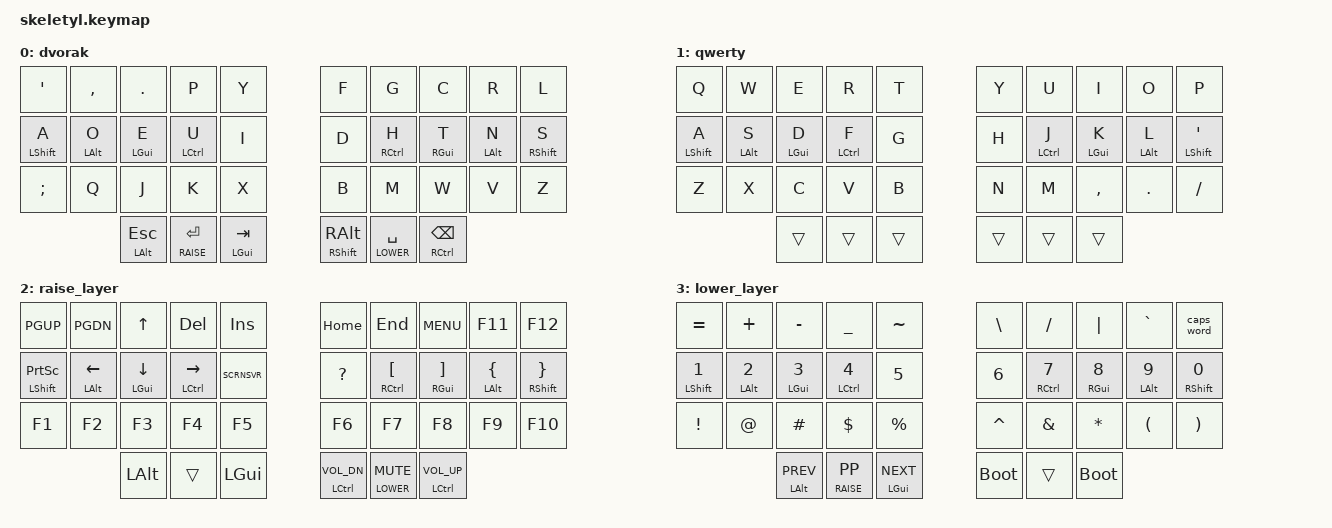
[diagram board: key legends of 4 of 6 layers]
#include <behaviors.dtsi>
#include <dt-bindings/zmk/keys.h>
#include <dt-bindings/zmk/bt.h>
#include <dt-bindings/zmk/pointing.h>
#include <dt-bindings/zmk/outputs.h>
#include "key-labels.h"

// Modified keymap based on personal experience, with some improvements based on Miryoku layout.

#define DVORAK      0
#define QWERTY      1
#define RAISE       2
#define LOWER       3
#define MOUSE       4
#define MOUSE_COND  5

#define REQUIRE_PRIOR_IDLE_MS 150
/* the default value of 280 is too flakey when the interrupting tap is pressed close to the hold */
#define TAPPING_TERM_MS 180
#define QUICK_TAP_MS 175

#define SCRNSVR K_SCREENSAVER

#define MOUSE_LAYER \
    &none          &none          &msc SCRL_UP&none   &none          &none          &none          &mmv MOVE_UP    &none          &none \
    &msc SCRL_LEFT &mkp LCLK      &mkp MCLK &mkp RCLK &msc SCRL_RIGHT&none          &mmv MOVE_LEFT &mmv MOVE_DOWN  &mmv MOVE_RIGHT&none \
    &trans         &trans         &msc SCRL_DOWN&trans&trans         &trans         &trans         &trans          &trans         &trans \
                                  &trans    &trans    &trans         &trans         &trans         &trans

&mt {
    quick-tap-ms = <QUICK_TAP_MS>;
};

&lt {
    quick-tap-ms = <QUICK_TAP_MS>;
};

&msc {
    x-input-code = <INPUT_REL_HWHEEL>;
    y-input-code = <INPUT_REL_WHEEL>;
    time-to-max-speed-ms = <300>;
    acceleration-exponent = <20>;
};

/ {
    behaviors {
        hml: home_row_mod_left {
            compatible = "zmk,behavior-hold-tap";
            #binding-cells = <2>;
            flavor = "balanced";
            require-prior-idle-ms = <REQUIRE_PRIOR_IDLE_MS>;
            tapping-term-ms = <TAPPING_TERM_MS>;
            quick-tap-ms = <QUICK_TAP_MS>;
            bindings = <&kp>, <&kp>;
            hold-trigger-key-positions = <RM1 RM2 RM3 RM4 RH0 RH1 RH2>; // List of keys on the right side of the keyboard
            hold-trigger-on-release;
        };
        hmr: home_row_mod_right {
            compatible = "zmk,behavior-hold-tap";
            #binding-cells = <2>;
            flavor = "balanced";
            require-prior-idle-ms = <REQUIRE_PRIOR_IDLE_MS>;
            tapping-term-ms = <TAPPING_TERM_MS>;
            quick-tap-ms = <QUICK_TAP_MS>;
            bindings = <&kp>, <&kp>;
            hold-trigger-key-positions = <LM1 LM2 LM3 LM4 LH0 LH1 LH2>; // List of keys on the left side of the keyboard
            hold-trigger-on-release;
        };

    };

    conditional_layers {
        compatible = "zmk,conditional-layers";
        tri_layer {
            if-layers = <RAISE LOWER>;
            then-layer = <MOUSE_COND>;
        };
    };

    combos {
        compatible = "zmk,combos";

        // Combo for toggling the Qwerty layout
        combo_tg_qwerty {
            timeout-ms = <50>;
            key-positions = <RT1 RT2 RT3>;
            bindings = <&tog QWERTY>;
        };

        combo_tg_mouse {
            timeout-ms = <50>;
            key-positions = <LT1 LT2 LT3>;
            bindings = <&tog MOUSE>;
        };

        // Combo for toggling output
        combo_tg_output {
            timeout-ms = <50>;
            key-positions = <LT0 LT4>;
            bindings = <&out OUT_TOG>;
        };

        // Combo for reseting bluetooth
        combo_tg_bt_reset {
            timeout-ms = <50>;
            key-positions = <LM0 LM4>;
            bindings = <&bt BT_CLR>;
        };

        // Combo for bootloader reset
        combo_bootloader_reset_left {
            timeout-ms = <50>;
            key-positions = <LB0 LB4>;
            bindings = <&bootloader>;
        };

        // Combo for bluetooth control (i.e. switch among the devices).
        combo_bt_next {
            timeout-ms = <50>;
            key-positions = <RB2 RB3>;
            bindings = <&bt BT_NXT>;
        };
        combo_bt_prev {
            timeout-ms = <50>;
            key-positions = <RB1 RB2>;
            bindings = <&bt BT_PRV>;
        };

    };

    keymap {
        compatible = "zmk,keymap";

 /* Base (dvorak)
 * ,---------------------------------------,                                  ,---------------------------------------,
 * |   '   |   ,   |   .   |   p   |   y   |                                  |   f   |   g   |   c   |   r   |   l   |
 * |-------+-------+-------+-------+-------|                                  |-------+-------+-------+-------+-------|
 * |   a   |   o   |   e   |   u   |   i   |                                  |   d   |   h   |   t   |   n   |   s   |
 * |-------+-------+-------+-------+-------|                                  |------ +-------+-------+-------+-------|
 * |   ;   |   q   |   j   |   k   |   x   |                                  |   b   |   m   |   w   |   v   |   z   |
 * '-----------------------------------------------------------,  ,---------------------------------------------------'
 *                                 |  ESC  | ENTER+RAISE | TAB |  | RALT| SPACE+LOWER |  BS  |
 *                                 '---------------------------'  '--------------------------'
 */

        dvorak {
            bindings = <
    &kp SQT        &kp COMMA      &kp DOT        &kp P          &kp Y          &kp F          &kp G           &kp C          &kp R          &kp L
    &hml LSHFT A   &hml LALT O    &hml LGUI E    &hml LCTRL U   &kp I          &kp D          &hmr RCTRL H    &hmr RGUI T    &hmr LALT N    &hmr RSHFT S
    &kp SEMI       &kp Q          &kp J          &kp K          &kp X          &kp B          &kp M           &kp W          &kp V          &kp Z
                                  &mt LALT ESC   &lt RAISE RET  &mt LGUI TAB   &mt RSHFT RALT &lt LOWER SPACE &mt RCTRL BSPC
            >;
        };

        qwerty {
            bindings = <
    &kp Q          &kp W          &kp E          &kp R          &kp T          &kp Y          &kp U           &kp I          &kp O          &kp P
    &hml LSHFT A   &hml LALT S    &hml LGUI D    &hml LCTRL F   &kp G          &kp H          &hmr LCTRL J    &hmr LGUI K    &hmr LALT L    &hmr LSHFT SQT
    &kp Z          &kp X          &kp C          &kp V          &kp B          &kp N          &kp M           &kp COMMA      &kp DOT        &kp FSLH
                                  &trans         &trans         &trans         &trans         &trans          &trans
            >;
        };

 /* Raise
 * ,---------------------------------------,                                  ,---------------------------------------,
 * | PGUP  | PGDN  |  up   |  DEL  |INSERT |                                  | HOME  |  END  | MENU  |  F11  |  F12  |
 * |-------+-------+-------+-------+-------|                                  |-------+-------+-------+-------+-------|
 * | PSCRN |  left |  down | right |SCRNSVR|                                  |   ?   |   [   |   ]   |   {   |   }   |
 * |-------+-------+-------+-------+-------|                                  |------ +-------+-------+-------+-------|
 * |   F1  |  F2   |  F3   |  F4   |  F5   |                                  |   F6  |  F7   |  F8   |  F9   |  F10  |
 * '-------------------------------------------------------,  ,-------------------------------------------------------'
 *                                 |       |       |       |  |VOL_DN|  MUTE  |VOL_UP |
 *                                 '-----------------------'  '-----------------------'
 */

        raise_layer {
            bindings = <
    &kp PGUP       &kp PGDN       &kp  UP        &kp  DEL       &kp INSERT     &kp HOME       &kp END        &kp K_MENU     &kp F11        &kp F12
    &hml LSHFT PSCRN&hml LALT LEFT&hml LGUI DOWN &hml LCTRL RIGHT&kp SCRNSVR   &kp QMARK      &hmr RCTRL LBKT&hmr RGUI RBKT &hmr LALT LBRC &hmr RSHFT RBRC
    &kp F1         &kp F2         &kp F3         &kp F4         &kp F5         &kp F6         &kp F7         &kp F8         &kp F9         &kp F10
                                  &kp LALT       &trans         &kp LGUI       &mt LCTRL K_VOL_DN&lt LOWER K_MUTE&mt LCTRL K_VOL_UP
            >;
        };

 /* Lower
 * ,---------------------------------------,                                  ,---------------------------------------,
 * |   =   |   +   |   -   |   _   |   ~   |                                  |   \   |   /   |   |   |   `   | CAPS  |
 * |-------+-------+-------+-------+-------|                                  |-------+-------+-------+-------+-------|
 * |   1   |   2   |   3   |   4   |   5   |                                  |   6   |   7   |   8   |   9   |   0   |
 * |-------+-------+-------+-------+-------|                                  |------ +-------+-------+-------+-------|
 * |   !   |   @   |   #   |   $   |   %   |                                  |   ^   |   &   |   *   |   (   |   )   |
 * '-------------------------------------------------------,  ,-------------------------------------------------------'
 *                                 | PREV  | PP    | NEXT  |  | RESET |       | RESET |
 *                                 '-----------------------'  '-----------------------'
 */

        lower_layer {
            bindings = <
    &kp EQUAL      &kp PLUS       &kp MINUS      &kp UNDER      &kp TILDE      &kp BSLH       &kp FSLH       &kp PIPE        &kp GRAVE      &caps_word
    &hml LSHFT N1  &hml LALT N2   &hml LGUI N3   &hml LCTRL N4  &kp N5         &kp N6         &hmr RCTRL N7  &hmr RGUI N8    &hmr LALT N9   &hmr RSHFT N0
    &kp EXCL       &kp AT         &kp HASH       &kp DLLR       &kp PRCNT      &kp CARET      &kp AMPS       &kp ASTRK       &kp LPAR       &kp RPAR
                                  &mt LALT K_PREV&lt RAISE K_PP &mt LGUI K_NEXT&bootloader    &trans         &bootloader
            >;
        };

 /* Mouse
 * ,---------------------------------------------------,                                  ,---------------------------------------,
 * |           |       | SCRL_UP   |       |           |                                  |       |       | MUP   |       |       |
 * |-----------+-------+-----------+-------+-----------|                                  |-------+-------+-------+-------+-------|
 * | SCRL_LEFT | LCLK  | MCLK      | RCLK  | SCRL_RIGHT|                                  |       | MLEFT | MDOWN | MRIGHT|       |
 * |-----------+-------+-----------+-------+-----------|                                  |------ +-------+-------+-------+-------|
 * |           |       | SCRL_DOWN |       |           |                                  |       |       |       |       |       |
 * '-------------------------------------------------------------------,  ,-------------------------------------------------------'
 *                                         |           |       |       |  |       |       |       |
 *                                         '---------------------------'  '-----------------------'
 */

        mouse_layer {
            bindings = <
                MOUSE_LAYER
            >;
        };

        mouse_cond_layer {
            bindings = <
                MOUSE_LAYER
            >;
        };
    };
};
